VERSION ""

NS_ :

BS_:

BU_: HMI1 HMI2 VCU BMS MCU

BO_ 3221225472 VECTOR__INDEPENDENT_SIG_MSG: 0 Vector__XXX
 SG_ DBG_VCU__State : 16|8@1- (1,0) [0|0] "" Vector__XXX

BO_ 1952 VCU_Heartbeat: 2 VCU
 SG_ VCU__Version : 0|16@1+ (1,0) [0|0] "" Vector__XXX

BO_ 1953 HMI1_Heartbeat: 2 HMI1
 SG_ HMI1__Version : 0|16@1+ (1,0) [0|0] ""  VCU

BO_ 1954 HMI2_Heartbeat: 2 HMI2
 SG_ HMI2__Version : 0|16@1+ (1,0) [0|0] ""  VCU

BO_ 26 DFU_Progress: 8 VCU
 SG_ DFU__DeviceType : 0|32@1+ (1,0) [0|0] ""  HMI1
 SG_ DFU__Progress : 32|32@1- (1,0) [0|0] "%"  HMI1

BO_ 27 DFU_CRC: 4 HMI1
 SG_ DFU__CurrentCRC : 0|32@1+ (1,0) [0|0] ""  VCU

BO_ 28 DFU_Pra: 4 VCU
 SG_ DFU__FirmwareSize : 0|32@1+ (1,0) [0|0] ""  HMI1

BO_ 29 DFU_Init: 6 VCU
 SG_ DFU__FirmwareOffset : 0|32@1+ (1,0) [0|0] ""  HMI1
 SG_ DFU__BlockOffset : 32|16@1+ (1,0) [0|0] ""  HMI1

BO_ 30 DFU_Run: 8 VCU
 SG_ DFU__SubBlockOffset : 0|16@1+ (1,0) [0|0] ""  HMI1
 SG_ DFU__FirmwareData : 32|32@1+ (1,0) [0|0] ""  HMI1

BO_ 31 DFU_Pasca: 4 VCU
 SG_ DFU__NewestCRC : 0|32@1+ (1,0) [0|0] ""  HMI1

BO_ 42 VCU_SwitchControl: 8 VCU
 SG_ VCU__ABS_State : 0|1@1+ (1,0) [0|0] ""  HMI1
 SG_ VCU__MirroringState : 1|1@1+ (1,0) [0|0] ""  HMI1
 SG_ VCU__LampState : 2|1@1+ (1,0) [0|0] ""  HMI1
 SG_ VCU__ErrorState : 3|1@1+ (1,0) [0|0] ""  HMI1
 SG_ VCU__OverheatState : 4|1@1+ (1,0) [0|0] ""  HMI1
 SG_ VCU__FingerState : 5|1@1+ (1,0) [0|0] ""  HMI1
 SG_ VCU__RemoteState : 6|1@1+ (1,0) [0|0] ""  HMI1
 SG_ VCU__DaylightState : 7|1@1+ (1,0) [0|0] ""  HMI1
 SG_ VCU__SeinLeftState : 8|1@1+ (1,0) [0|0] ""  HMI1
 SG_ VCU__SeinRightState : 9|1@1+ (1,0) [0|0] ""  HMI1
 SG_ VCU__HbarReverseState : 10|1@1+ (1,0) [0|0] ""  HMI1
 SG_ VCU__BMSRun : 11|1@1+ (1,0) [0|0] ""  HMI1
 SG_ VCU__MCURun : 12|1@1+ (1,0) [0|0] ""  HMI1
 SG_ VCU__FingerBlink : 13|1@1+ (1,0) [0|0] ""  HMI1
 SG_ VCU__FingerError : 14|1@1+ (1,0) [0|0] ""  HMI1
 SG_ VCU__DriveMode : 16|2@1+ (1,0) [0|0] ""  HMI1
 SG_ VCU__TripMode : 18|2@1+ (1,0) [0|0] ""  HMI1
 SG_ VCU__ReportMode : 20|1@1+ (1,0) [0|0] ""  HMI1
 SG_ VCU__ModeState : 21|2@1+ (1,0) [0|0] ""  HMI1
 SG_ VCU__ModeSession : 23|1@1+ (1,0) [0|0] ""  HMI1
 SG_ VCU__Speed : 24|8@1+ (1,0) [0|0] "kph"  HMI1
 SG_ VCU__MCUDisCur : 32|8@1+ (1,0) [0|0] "A"  HMI1
 SG_ VCU__BMSSoc : 40|8@1+ (1,0) [0|0] "%"  HMI1
 SG_ VCU__NetSignal : 48|8@1+ (1,0) [0|0] "%"  HMI1
 SG_ VCU__VehicleState : 56|8@1- (1,0) [0|0] ""  HMI1

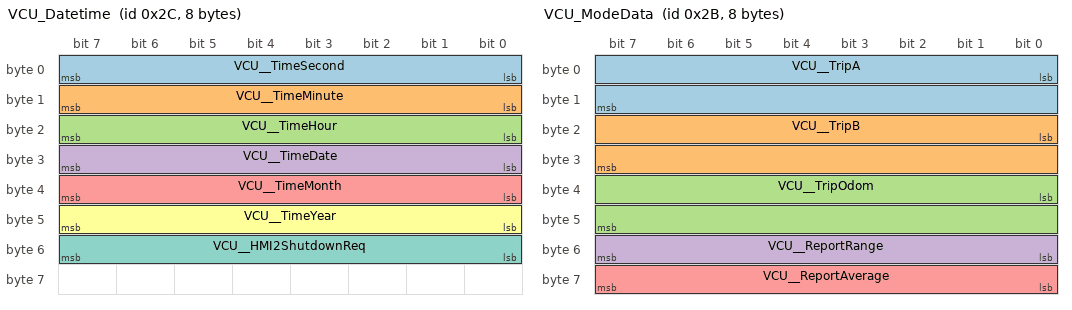
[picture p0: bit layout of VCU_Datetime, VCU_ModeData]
BO_ 44 VCU_Datetime: 8 VCU
 SG_ VCU__TimeSecond : 0|8@1+ (1,0) [0|0] ""  HMI2
 SG_ VCU__TimeMinute : 8|8@1+ (1,0) [0|0] ""  HMI2
 SG_ VCU__TimeHour : 16|8@1+ (1,0) [0|0] ""  HMI2
 SG_ VCU__TimeDate : 24|8@1+ (1,0) [0|0] ""  HMI2
 SG_ VCU__TimeMonth : 32|8@1+ (1,0) [0|0] ""  HMI2
 SG_ VCU__TimeYear : 40|8@1+ (1,0) [0|0] ""  HMI2
 SG_ VCU__HMI2ShutdownReq : 48|8@1+ (1,0) [0|0] ""  HMI2

BO_ 43 VCU_ModeData: 8 VCU
 SG_ VCU__TripA : 0|16@1+ (1,0) [0|0] "km"  HMI1
 SG_ VCU__TripB : 16|16@1+ (1,0) [0|0] "km"  HMI1
 SG_ VCU__TripOdom : 32|16@1+ (1,0) [0|0] "km"  HMI1
 SG_ VCU__ReportRange : 48|8@1+ (1,0) [0|0] "km"  HMI1
 SG_ VCU__ReportAverage : 56|8@1+ (1,0) [0|0] "km/kwh"  HMI1

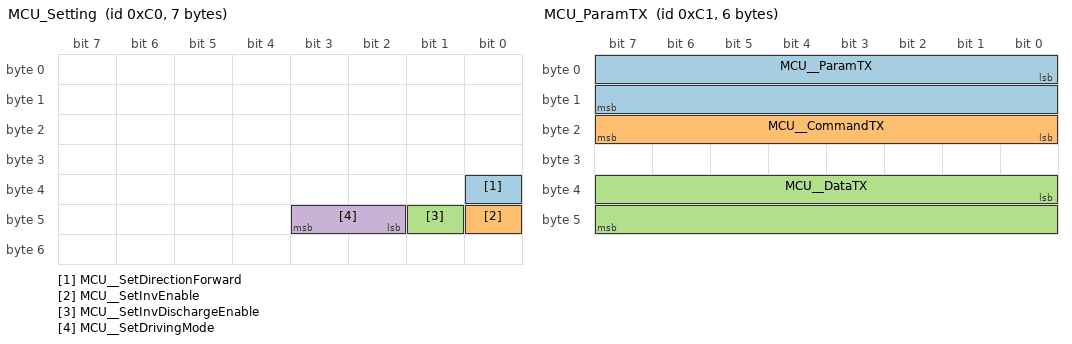
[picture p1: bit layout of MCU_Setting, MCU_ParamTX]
BO_ 192 MCU_Setting: 7 VCU
 SG_ MCU__SetDirectionForward : 32|1@1+ (1,0) [0|0] ""  MCU
 SG_ MCU__SetInvEnable : 40|1@1+ (1,0) [0|0] ""  MCU
 SG_ MCU__SetInvDischargeEnable : 41|1@1+ (1,0) [0|0] ""  MCU
 SG_ MCU__SetDrivingMode : 42|2@1+ (1,0) [0|0] ""  MCU

BO_ 193 MCU_ParamTX: 6 VCU
 SG_ MCU__ParamTX : 0|16@1+ (1,0) [0|0] ""  MCU
 SG_ MCU__CommandTX : 16|8@1+ (1,0) [0|0] ""  MCU
 SG_ MCU__DataTX : 32|16@1+ (1,0) [0|0] ""  MCU

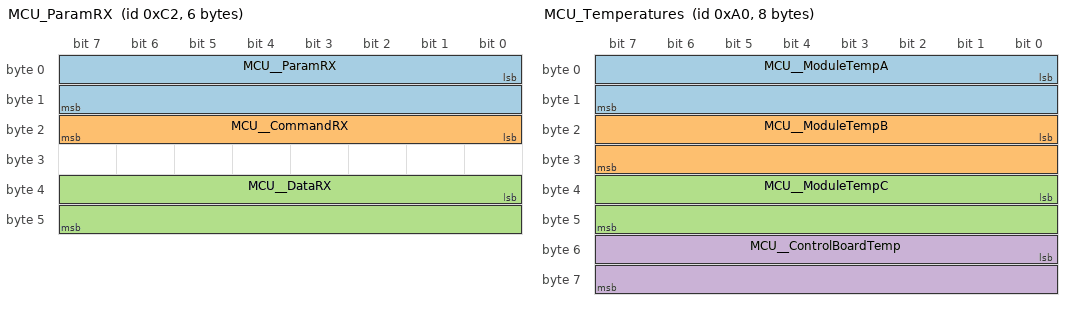
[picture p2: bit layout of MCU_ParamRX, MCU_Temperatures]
BO_ 194 MCU_ParamRX: 6 MCU
 SG_ MCU__ParamRX : 0|16@1+ (1,0) [0|0] ""  VCU
 SG_ MCU__CommandRX : 16|8@1+ (1,0) [0|0] ""  VCU
 SG_ MCU__DataRX : 32|16@1+ (1,0) [0|0] ""  VCU

BO_ 160 MCU_Temperatures: 8 MCU
 SG_ MCU__ModuleTempA : 0|16@1- (0.1,0) [0|0] "C"  VCU
 SG_ MCU__ModuleTempB : 16|16@1- (0.1,0) [0|0] "C"  VCU
 SG_ MCU__ModuleTempC : 32|16@1- (0.1,0) [0|0] "C"  VCU
 SG_ MCU__ControlBoardTemp : 48|16@1- (0.1,0) [0|0] "C"  VCU

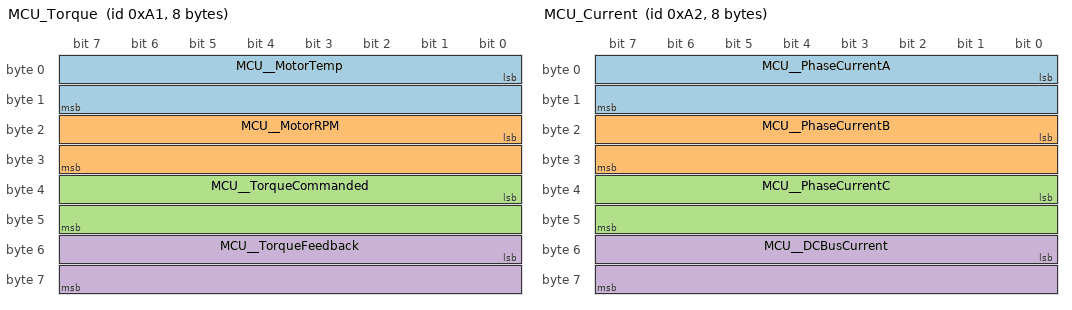
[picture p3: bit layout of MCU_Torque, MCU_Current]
BO_ 161 MCU_Torque: 8 MCU
 SG_ MCU__MotorTemp : 0|16@1- (0.1,0) [0|0] "C"  VCU
 SG_ MCU__MotorRPM : 16|16@1- (1,0) [0|0] "rpm"  VCU
 SG_ MCU__TorqueCommanded : 32|16@1- (0.1,0) [0|0] "Nm"  VCU
 SG_ MCU__TorqueFeedback : 48|16@1- (0.1,0) [0|0] "Nm"  VCU

BO_ 162 MCU_Current: 8 MCU
 SG_ MCU__PhaseCurrentA : 0|16@1- (0.1,0) [0|0] "A"  VCU
 SG_ MCU__PhaseCurrentB : 16|16@1- (0.1,0) [0|0] "A"  VCU
 SG_ MCU__PhaseCurrentC : 32|16@1- (0.1,0) [0|0] "A"  VCU
 SG_ MCU__DCBusCurrent : 48|16@1- (0.1,0) [0|0] "A"  VCU

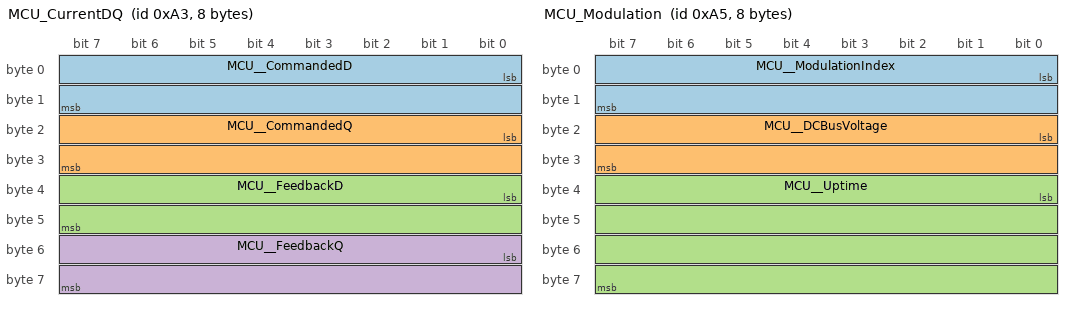
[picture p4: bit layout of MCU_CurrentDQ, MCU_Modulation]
BO_ 163 MCU_CurrentDQ: 8 MCU
 SG_ MCU__CommandedD : 0|16@1- (0.1,0) [0|0] "A"  VCU
 SG_ MCU__CommandedQ : 16|16@1- (0.1,0) [0|0] "A"  VCU
 SG_ MCU__FeedbackD : 32|16@1- (0.1,0) [0|0] "A"  VCU
 SG_ MCU__FeedbackQ : 48|16@1- (0.1,0) [0|0] "A"  VCU

BO_ 164 MCU_FaultCodes: 8 MCU
 SG_ MCU__FaultPOST : 0|32@1+ (1,0) [0|0] ""  VCU
 SG_ MCU__FaultRUN : 32|32@1+ (1,0) [0|0] ""  VCU

BO_ 165 MCU_Modulation: 8 MCU
 SG_ MCU__ModulationIndex : 0|16@1- (0.001,0) [0|0] ""  VCU
 SG_ MCU__DCBusVoltage : 16|16@1- (0.1,0) [0|0] "V"  VCU
 SG_ MCU__Uptime : 32|32@1+ (0.003,0) [0|0] "s"  VCU

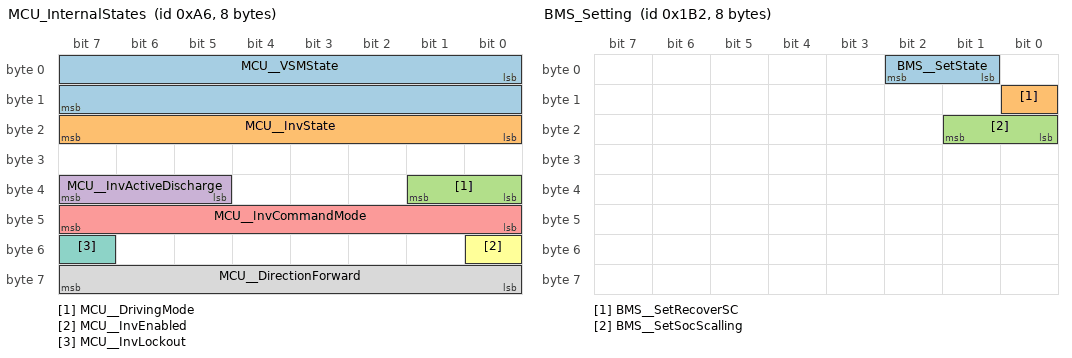
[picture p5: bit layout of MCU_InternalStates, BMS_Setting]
BO_ 166 MCU_InternalStates: 8 MCU
 SG_ MCU__VSMState : 0|16@1+ (1,0) [0|0] ""  VCU
 SG_ MCU__InvState : 16|8@1+ (1,0) [0|0] ""  VCU
 SG_ MCU__DrivingMode : 32|2@1+ (1,0) [0|0] ""  VCU
 SG_ MCU__InvActiveDischarge : 37|3@1+ (1,0) [0|0] ""  VCU
 SG_ MCU__InvCommandMode : 40|8@1+ (1,0) [0|0] ""  VCU
 SG_ MCU__InvEnabled : 48|1@1+ (1,0) [0|0] ""  VCU
 SG_ MCU__InvLockout : 55|1@1+ (1,0) [0|0] ""  VCU
 SG_ MCU__DirectionForward : 56|8@1+ (1,0) [0|0] ""  VCU

BO_ 434 BMS_Setting: 8 VCU
 SG_ BMS__SetState : 1|2@1+ (1,0) [0|0] ""  BMS
 SG_ BMS__SetRecoverSC : 8|1@1+ (1,0) [0|0] ""  BMS
 SG_ BMS__SetSocScalling : 16|2@1+ (1,0) [0|0] ""  BMS

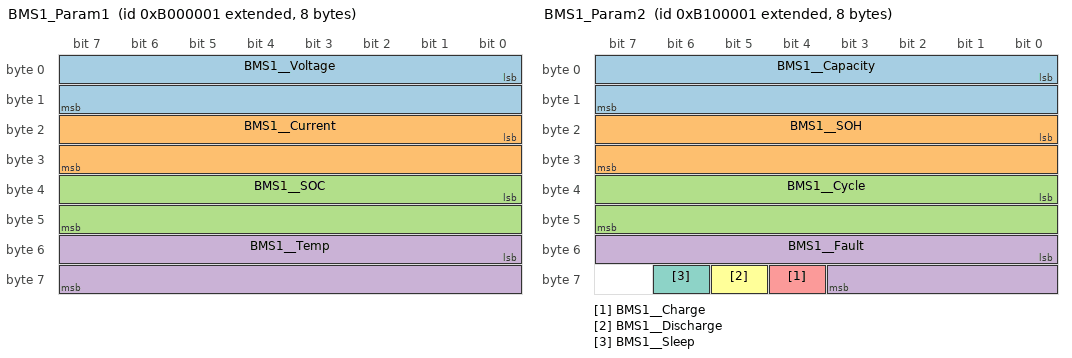
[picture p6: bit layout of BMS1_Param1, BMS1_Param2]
BO_ 2332033025 BMS1_Param1: 8 BMS
 SG_ BMS1__Voltage : 0|16@1+ (0.01,0) [0|0] "V"  VCU
 SG_ BMS1__Current : 16|16@1+ (0.1,0) [0|0] "A"  VCU
 SG_ BMS1__SOC : 32|16@1+ (1,0) [0|0] "%"  VCU
 SG_ BMS1__Temp : 48|16@1+ (1,-40) [0|0] "C"  VCU

BO_ 2333081601 BMS1_Param2: 8 BMS
 SG_ BMS1__Capacity : 0|16@1+ (0.1,0) [0|0] "Ah"  VCU
 SG_ BMS1__SOH : 16|16@1+ (1,0) [0|0] "%"  VCU
 SG_ BMS1__Cycle : 32|16@1+ (1,0) [0|0] ""  VCU
 SG_ BMS1__Fault : 48|12@1+ (1,0) [0|0] ""  VCU
 SG_ BMS1__Charge : 60|1@1+ (1,0) [0|0] ""  VCU
 SG_ BMS1__Discharge : 61|1@1+ (1,0) [0|0] ""  VCU
 SG_ BMS1__Sleep : 62|1@1+ (1,0) [0|0] ""  VCU

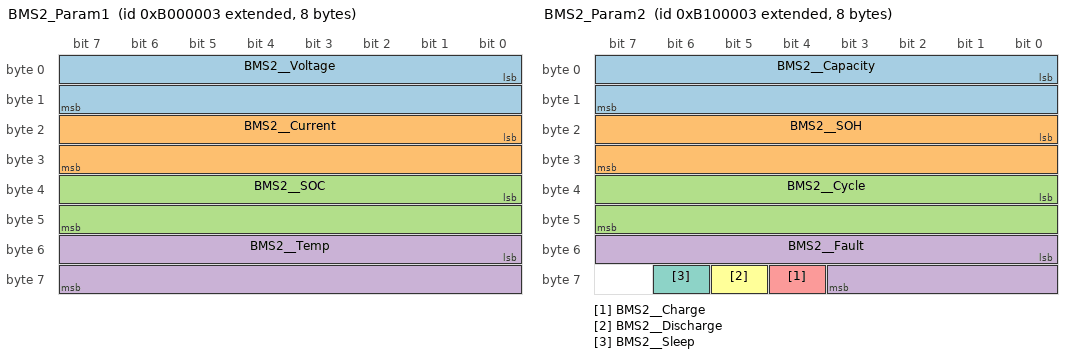
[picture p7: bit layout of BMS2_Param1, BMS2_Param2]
BO_ 2332033027 BMS2_Param1: 8 BMS
 SG_ BMS2__Voltage : 0|16@1+ (0.01,0) [0|0] "V"  VCU
 SG_ BMS2__Current : 16|16@1+ (0.1,0) [0|0] "A"  VCU
 SG_ BMS2__SOC : 32|16@1+ (1,0) [0|0] "%"  VCU
 SG_ BMS2__Temp : 48|16@1+ (1,-40) [0|0] "C"  VCU

BO_ 2333081603 BMS2_Param2: 8 BMS
 SG_ BMS2__Capacity : 0|16@1+ (0.1,0) [0|0] "Ah"  VCU
 SG_ BMS2__SOH : 16|16@1+ (1,0) [0|0] "%"  VCU
 SG_ BMS2__Cycle : 32|16@1+ (1,0) [0|0] ""  VCU
 SG_ BMS2__Fault : 48|12@1+ (1,0) [0|0] ""  VCU
 SG_ BMS2__Charge : 60|1@1+ (1,0) [0|0] ""  VCU
 SG_ BMS2__Discharge : 61|1@1+ (1,0) [0|0] ""  VCU
 SG_ BMS2__Sleep : 62|1@1+ (1,0) [0|0] ""  VCU

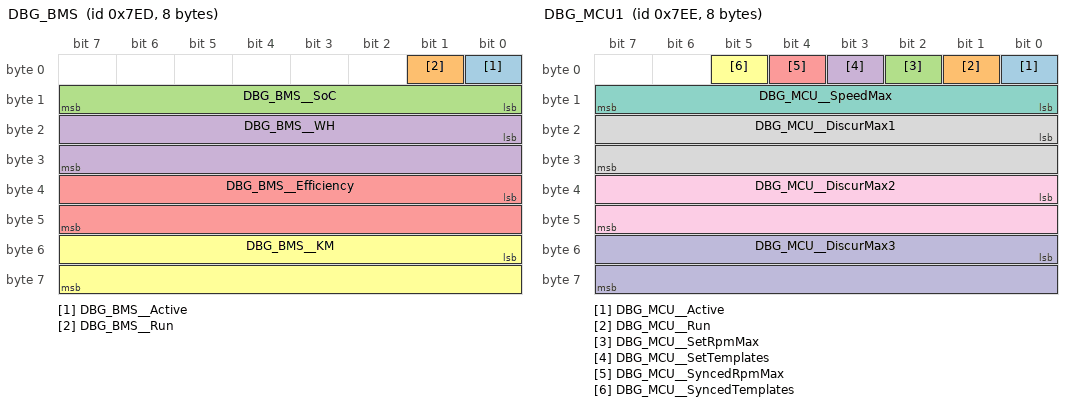
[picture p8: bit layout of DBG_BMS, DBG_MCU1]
BO_ 2029 DBG_BMS: 8 VCU
 SG_ DBG_BMS__Active : 0|1@1+ (1,0) [0|0] "" Vector__XXX
 SG_ DBG_BMS__Run : 1|1@1+ (1,0) [0|0] "" Vector__XXX
 SG_ DBG_BMS__SoC : 8|8@1+ (1,0) [0|0] "%" Vector__XXX
 SG_ DBG_BMS__WH : 16|16@1+ (0.1,0) [0|0] "wh" Vector__XXX
 SG_ DBG_BMS__Efficiency : 32|16@1+ (0.1,0) [0|0] "km/kwh" Vector__XXX
 SG_ DBG_BMS__KM : 48|16@1+ (0.1,0) [0|0] "km" Vector__XXX

BO_ 2030 DBG_MCU1: 8 VCU
 SG_ DBG_MCU__Active : 0|1@1+ (1,0) [0|0] "" Vector__XXX
 SG_ DBG_MCU__Run : 1|1@1+ (1,0) [0|0] "" Vector__XXX
 SG_ DBG_MCU__SetRpmMax : 2|1@1+ (1,0) [0|0] "rpm" Vector__XXX
 SG_ DBG_MCU__SetTemplates : 3|1@1+ (1,0) [0|0] "" Vector__XXX
 SG_ DBG_MCU__SyncedRpmMax : 4|1@1+ (1,0) [0|0] "" Vector__XXX
 SG_ DBG_MCU__SyncedTemplates : 5|1@1+ (1,0) [0|0] "" Vector__XXX
 SG_ DBG_MCU__SpeedMax : 8|8@1+ (1,0) [0|0] "kph" Vector__XXX
 SG_ DBG_MCU__DiscurMax1 : 16|16@1- (1,0) [0|0] "A" Vector__XXX
 SG_ DBG_MCU__DiscurMax2 : 32|16@1- (1,0) [0|0] "A" Vector__XXX
 SG_ DBG_MCU__DiscurMax3 : 48|16@1- (1,0) [0|0] "A" Vector__XXX

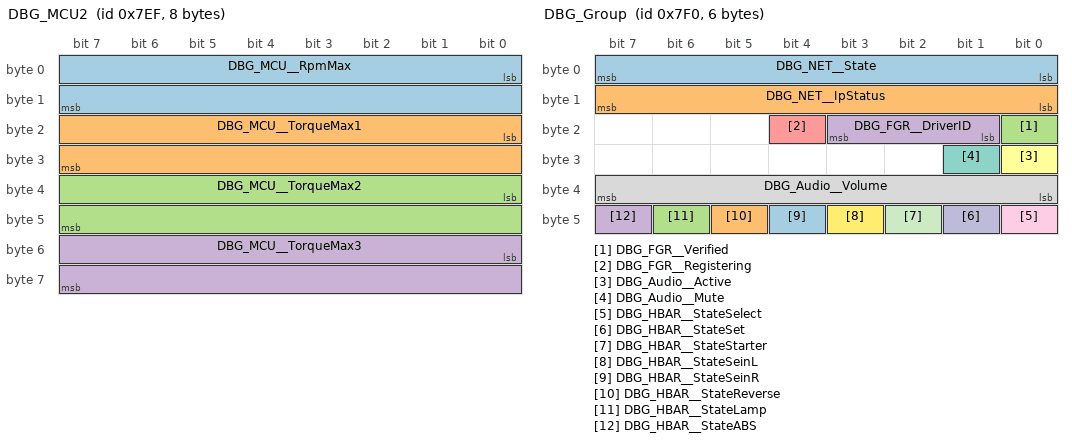
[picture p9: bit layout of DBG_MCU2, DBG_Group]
BO_ 2031 DBG_MCU2: 8 VCU
 SG_ DBG_MCU__RpmMax : 0|16@1- (1,0) [0|0] "rpm" Vector__XXX
 SG_ DBG_MCU__TorqueMax1 : 16|16@1- (0.1,0) [0|0] "Nm" Vector__XXX
 SG_ DBG_MCU__TorqueMax2 : 32|16@1- (0.1,0) [0|0] "Nm" Vector__XXX
 SG_ DBG_MCU__TorqueMax3 : 48|16@1- (0.1,0) [0|0] "Nm" Vector__XXX

BO_ 2032 DBG_Group: 6 VCU
 SG_ DBG_NET__State : 0|8@1- (1,0) [0|0] "" Vector__XXX
 SG_ DBG_NET__IpStatus : 8|8@1- (1,0) [0|0] "" Vector__XXX
 SG_ DBG_FGR__Verified : 16|1@1+ (1,0) [0|0] "" Vector__XXX
 SG_ DBG_FGR__DriverID : 17|3@1+ (1,0) [0|0] "" Vector__XXX
 SG_ DBG_FGR__Registering : 20|1@1+ (1,0) [0|0] "" Vector__XXX
 SG_ DBG_Audio__Active : 24|1@1+ (1,0) [0|0] "" Vector__XXX
 SG_ DBG_Audio__Mute : 25|1@1+ (1,0) [0|0] "" Vector__XXX
 SG_ DBG_Audio__Volume : 32|8@1+ (1,0) [0|0] "%" Vector__XXX
 SG_ DBG_HBAR__StateSelect : 40|1@1+ (1,0) [0|0] "" Vector__XXX
 SG_ DBG_HBAR__StateSet : 41|1@1+ (1,0) [0|0] "" Vector__XXX
 SG_ DBG_HBAR__StateStarter : 42|1@1+ (1,0) [0|0] "" Vector__XXX
 SG_ DBG_HBAR__StateSeinL : 43|1@1+ (1,0) [0|0] "" Vector__XXX
 SG_ DBG_HBAR__StateSeinR : 44|1@1+ (1,0) [0|0] "" Vector__XXX
 SG_ DBG_HBAR__StateReverse : 45|1@1+ (1,0) [0|0] "" Vector__XXX
 SG_ DBG_HBAR__StateLamp : 46|1@1+ (1,0) [0|0] "" Vector__XXX
 SG_ DBG_HBAR__StateABS : 47|1@1+ (1,0) [0|0] "" Vector__XXX

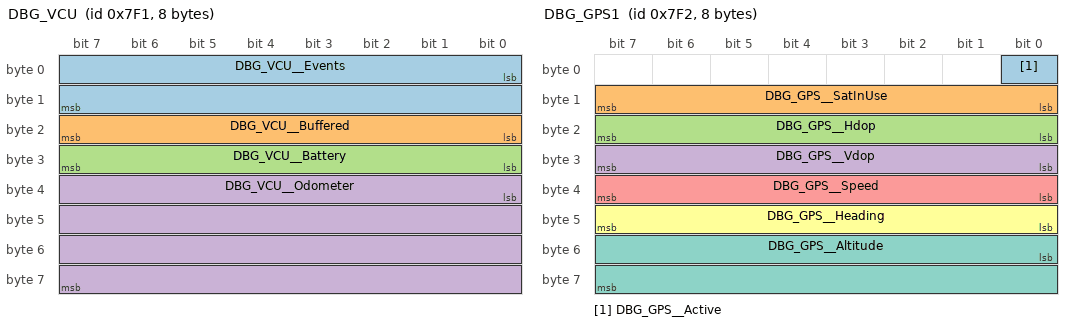
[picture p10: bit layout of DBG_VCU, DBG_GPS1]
BO_ 2033 DBG_VCU: 8 VCU
 SG_ DBG_VCU__Events : 0|16@1+ (1,0) [0|0] "" Vector__XXX
 SG_ DBG_VCU__Buffered : 16|8@1+ (1,0) [0|0] "" Vector__XXX
 SG_ DBG_VCU__Battery : 24|8@1+ (18,0) [0|0] "mV" Vector__XXX
 SG_ DBG_VCU__Odometer : 32|32@1+ (1,0) [0|0] "m" Vector__XXX

BO_ 2034 DBG_GPS1: 8 VCU
 SG_ DBG_GPS__Active : 0|1@1+ (1,0) [0|0] "" Vector__XXX
 SG_ DBG_GPS__SatInUse : 8|8@1+ (1,0) [0|0] "" Vector__XXX
 SG_ DBG_GPS__Hdop : 16|8@1+ (0.1,0) [0|0] "" Vector__XXX
 SG_ DBG_GPS__Vdop : 24|8@1+ (0.1,0) [0|0] "" Vector__XXX
 SG_ DBG_GPS__Speed : 32|8@1+ (1,0) [0|0] "kph" Vector__XXX
 SG_ DBG_GPS__Heading : 40|8@1+ (2,0) [0|0] "deg" Vector__XXX
 SG_ DBG_GPS__Altitude : 48|16@1+ (0.1,0) [0|0] "m" Vector__XXX

BO_ 2035 DBG_GPS2: 8 VCU
 SG_ DBG_GPS__Longitude : 0|32@1- (1e-07,0) [0|0] "" Vector__XXX
 SG_ DBG_GPS__Latitude : 32|32@1- (1e-07,0) [0|0] "" Vector__XXX

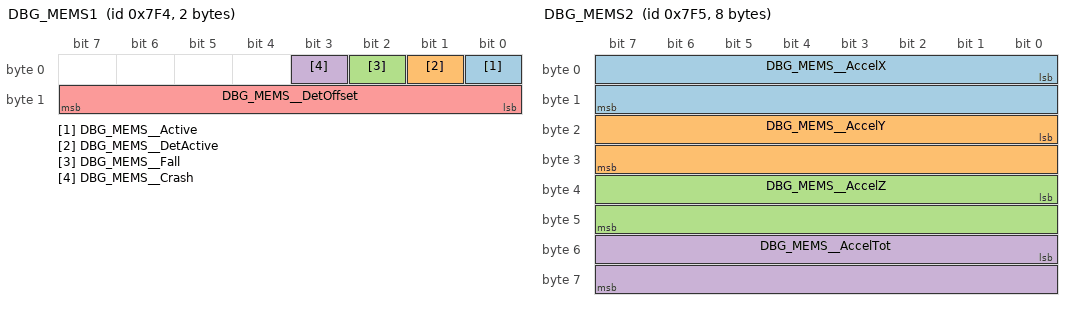
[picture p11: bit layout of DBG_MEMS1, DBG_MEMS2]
BO_ 2036 DBG_MEMS1: 2 VCU
 SG_ DBG_MEMS__Active : 0|1@1+ (1,0) [0|0] "" Vector__XXX
 SG_ DBG_MEMS__DetActive : 1|1@1+ (1,0) [0|0] "" Vector__XXX
 SG_ DBG_MEMS__Fall : 2|1@1+ (1,0) [0|0] "" Vector__XXX
 SG_ DBG_MEMS__Crash : 3|1@1+ (1,0) [0|0] "" Vector__XXX
 SG_ DBG_MEMS__DetOffset : 8|8@1+ (1,0) [0|0] "deg" Vector__XXX

BO_ 2037 DBG_MEMS2: 8 VCU
 SG_ DBG_MEMS__AccelX : 0|16@1- (0.01,0) [0|0] "g" Vector__XXX
 SG_ DBG_MEMS__AccelY : 16|16@1- (0.01,0) [0|0] "g" Vector__XXX
 SG_ DBG_MEMS__AccelZ : 32|16@1- (0.01,0) [0|0] "g" Vector__XXX
 SG_ DBG_MEMS__AccelTot : 48|16@1+ (0.01,0) [0|0] "g" Vector__XXX

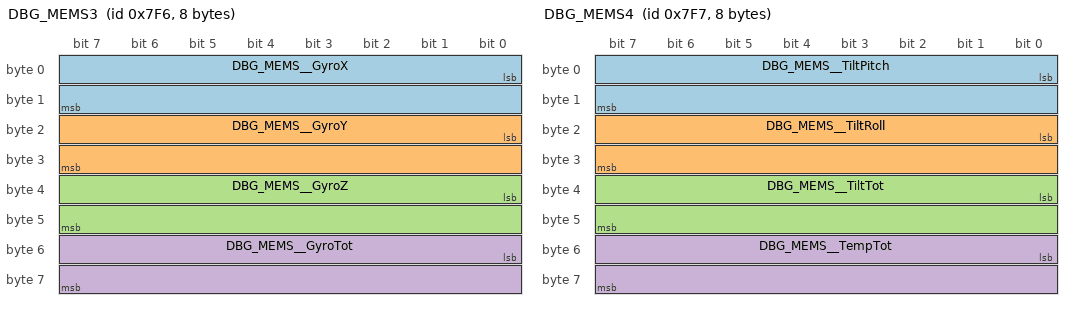
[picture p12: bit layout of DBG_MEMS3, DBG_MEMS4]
BO_ 2038 DBG_MEMS3: 8 VCU
 SG_ DBG_MEMS__GyroX : 0|16@1- (0.1,0) [0|0] "rad/s" Vector__XXX
 SG_ DBG_MEMS__GyroY : 16|16@1- (0.1,0) [0|0] "rad/s" Vector__XXX
 SG_ DBG_MEMS__GyroZ : 32|16@1- (0.1,0) [0|0] "rad/s" Vector__XXX
 SG_ DBG_MEMS__GyroTot : 48|16@1+ (0.1,0) [0|0] "rad/s" Vector__XXX

BO_ 2039 DBG_MEMS4: 8 VCU
 SG_ DBG_MEMS__TiltPitch : 0|16@1- (0.1,0) [0|0] "deg" Vector__XXX
 SG_ DBG_MEMS__TiltRoll : 16|16@1- (0.1,0) [0|0] "deg" Vector__XXX
 SG_ DBG_MEMS__TiltTot : 32|16@1+ (0.1,0) [0|0] "deg" Vector__XXX
 SG_ DBG_MEMS__TempTot : 48|16@1+ (0.1,0) [0|0] "C" Vector__XXX

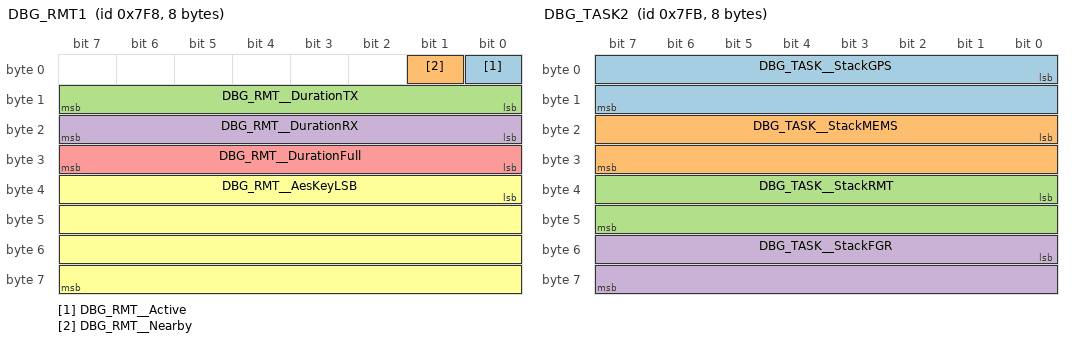
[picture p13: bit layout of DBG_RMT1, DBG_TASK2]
BO_ 2040 DBG_RMT1: 8 VCU
 SG_ DBG_RMT__Active : 0|1@1+ (1,0) [0|0] "" Vector__XXX
 SG_ DBG_RMT__Nearby : 1|1@1+ (1,0) [0|0] "" Vector__XXX
 SG_ DBG_RMT__DurationTX : 8|8@1+ (1,0) [0|0] "ms" Vector__XXX
 SG_ DBG_RMT__DurationRX : 16|8@1+ (1,0) [0|0] "ms" Vector__XXX
 SG_ DBG_RMT__DurationFull : 24|8@1+ (1,0) [0|0] "ms" Vector__XXX
 SG_ DBG_RMT__AesKeyLSB : 32|32@1+ (1,0) [0|0] "" Vector__XXX

BO_ 2041 DBG_RMT2: 8 VCU
 SG_ DBG_RMT__TickPing : 0|32@1+ (1,0) [0|0] "" Vector__XXX
 SG_ DBG_RMT__TickHeartbeat : 32|32@1+ (1,0) [0|0] "" Vector__XXX

BO_ 2042 DBG_TASK1: 8 VCU
 SG_ DBG_TASK__StackManager : 0|16@1+ (1,0) [0|0] "B" Vector__XXX
 SG_ DBG_TASK__StackNetwork : 16|16@1+ (1,0) [0|0] "B" Vector__XXX
 SG_ DBG_TASK__StackReporter : 32|16@1+ (1,0) [0|0] "B" Vector__XXX
 SG_ DBG_TASK__StackCommand : 40|16@1+ (1,0) [0|0] "B" Vector__XXX

BO_ 2043 DBG_TASK2: 8 VCU
 SG_ DBG_TASK__StackGPS : 0|16@1+ (1,0) [0|0] "B" Vector__XXX
 SG_ DBG_TASK__StackMEMS : 16|16@1+ (1,0) [0|0] "B" Vector__XXX
 SG_ DBG_TASK__StackRMT : 32|16@1+ (1,0) [0|0] "B" Vector__XXX
 SG_ DBG_TASK__StackFGR : 48|16@1+ (1,0) [0|0] "B" Vector__XXX

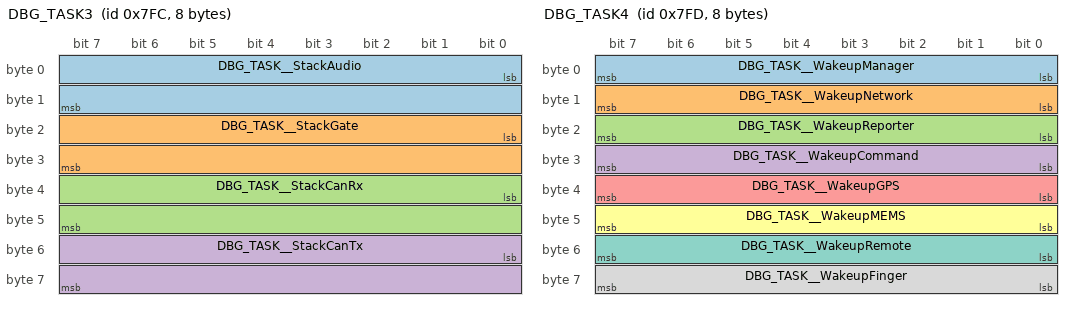
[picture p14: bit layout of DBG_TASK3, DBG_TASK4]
BO_ 2044 DBG_TASK3: 8 VCU
 SG_ DBG_TASK__StackAudio : 0|16@1+ (1,0) [0|0] "B" Vector__XXX
 SG_ DBG_TASK__StackGate : 16|16@1+ (1,0) [0|0] "B" Vector__XXX
 SG_ DBG_TASK__StackCanRx : 32|16@1+ (1,0) [0|0] "B" Vector__XXX
 SG_ DBG_TASK__StackCanTx : 48|16@1+ (1,0) [0|0] "B" Vector__XXX

BO_ 2045 DBG_TASK4: 8 VCU
 SG_ DBG_TASK__WakeupManager : 0|8@1+ (1,0) [0|0] "s" Vector__XXX
 SG_ DBG_TASK__WakeupNetwork : 8|8@1+ (1,0) [0|0] "s" Vector__XXX
 SG_ DBG_TASK__WakeupReporter : 16|8@1+ (1,0) [0|0] "s" Vector__XXX
 SG_ DBG_TASK__WakeupCommand : 24|8@1+ (1,0) [0|0] "s" Vector__XXX
 SG_ DBG_TASK__WakeupGPS : 32|8@1+ (1,0) [0|0] "s" Vector__XXX
 SG_ DBG_TASK__WakeupMEMS : 40|8@1+ (1,0) [0|0] "s" Vector__XXX
 SG_ DBG_TASK__WakeupRemote : 48|8@1+ (1,0) [0|0] "s" Vector__XXX
 SG_ DBG_TASK__WakeupFinger : 56|8@1+ (1,0) [0|0] "s" Vector__XXX

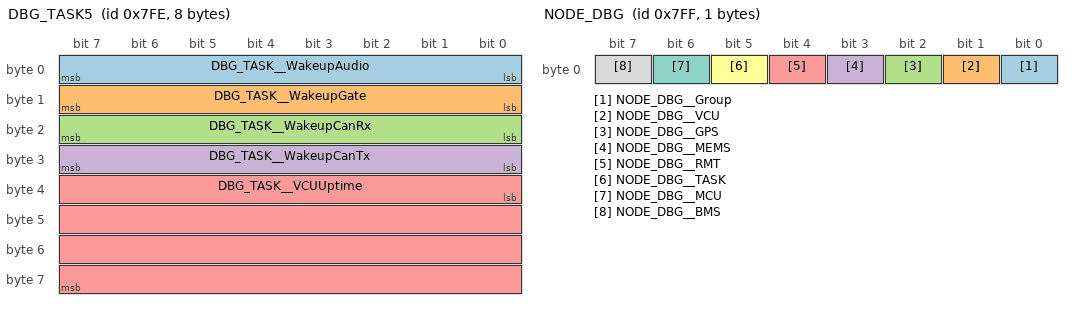
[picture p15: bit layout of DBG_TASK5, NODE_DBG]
BO_ 2046 DBG_TASK5: 8 VCU
 SG_ DBG_TASK__WakeupAudio : 0|8@1+ (1,0) [0|0] "s" Vector__XXX
 SG_ DBG_TASK__WakeupGate : 8|8@1+ (1,0) [0|0] "s" Vector__XXX
 SG_ DBG_TASK__WakeupCanRx : 16|8@1+ (1,0) [0|0] "s" Vector__XXX
 SG_ DBG_TASK__WakeupCanTx : 24|8@1+ (1,0) [0|0] "s" Vector__XXX
 SG_ DBG_TASK__VCUUptime : 32|32@1+ (1,0) [0|0] "s" Vector__XXX

BO_ 2047 NODE_DBG: 1 Vector__XXX
 SG_ NODE_DBG__Group : 0|1@1+ (1,0) [0|0] ""  VCU
 SG_ NODE_DBG__VCU : 1|1@1+ (1,0) [0|0] ""  VCU
 SG_ NODE_DBG__GPS : 2|1@1+ (1,0) [0|0] ""  VCU
 SG_ NODE_DBG__MEMS : 3|1@1+ (1,0) [0|0] ""  VCU
 SG_ NODE_DBG__RMT : 4|1@1+ (1,0) [0|0] ""  VCU
 SG_ NODE_DBG__TASK : 5|1@1+ (1,0) [0|0] ""  VCU
 SG_ NODE_DBG__MCU : 6|1@1+ (1,0) [0|0] ""  VCU
 SG_ NODE_DBG__BMS : 7|1@1+ (1,0) [0|0] "" Vector__XXX

BA_DEF_ BO_  "GenMsgBackgroundColor" STRING ;
BA_DEF_ BO_  "GenMsgForegroundColor" STRING ;
BA_DEF_DEF_  "GenMsgBackgroundColor" "#ffffff";
BA_DEF_DEF_  "GenMsgForegroundColor" "#000000";
VAL_ 42 VCU__DriveMode 0 "HBAR_M_DRIVE_ECONOMY" 1 "HBAR_M_DRIVE_STANDARD" 2 "HBAR_M_DRIVE_SPORT" ;
VAL_ 42 VCU__TripMode 0 "HBAR_M_TRIP_A" 1 "HBAR_M_TRIP_B" 2 "HBAR_M_TRIP_ODO" ;
VAL_ 42 VCU__ReportMode 0 "HBAR_M_REPORT_RANGE" 1 "HBAR_M_REPORT_AVERAGE" ;
VAL_ 42 VCU__ModeState 0 "HBAR_M_DRIVE" 1 "HBAR_M_TRIP" 2 "HBAR_M_REPORT" ;
VAL_ 42 VCU__VehicleState 0 "VEHICLE_NORMAL" 1 "VEHICLE_STANDBY" 2 "VEHICLE_READY" 3 "VEHICLE_RUN" ;
VAL_ 192 MCU__SetDrivingMode 0 "MCU_DRIVE_ECONOMIC" 1 "MCU_DRIVE_STANDARD" 2 "MCU_DRIVE_SPORT" ;
VAL_ 166 MCU__DrivingMode 0 "MCU_DRIVE_ECONOMIC" 1 "MCU_DRIVE_STANDARD" 2 "MCU_DRIVE_SPORT" ;
VAL_ 434 BMS__SetState 0 "BMS_IDLE" 1 "BMS_DISCHARGE" 2 "BMS_CHARGE" 3 "BMS_FULL" ;
VAL_ 434 BMS__SetSocScalling 0 "SCALE_15_85" 1 "SCALE_20_80" 2 "SCALE_10_90" 3 "SCALE_0_100" ;
VAL_ 2032 DBG_NET__State -1 "SIM_STATE_DOWN" 0 "SIM_STATE_READY" 1 "SIM_STATE_CONFIGURED" 2 "SIM_STATE_NETWORK_ON" 3 "SIM_STATE_GPRS_ON" 4 "SIM_STATE_PDP_ON" 5 "SIM_STATE_INTERNET_ON" 6 "SIM_STATE_SERVER_ON" 7 "SIM_STATE_MQTT_ON" ;
VAL_ 2032 DBG_NET__IpStatus -1 "CIPSTAT_UNKNOWN" 0 "CIPSTAT_IP_INITIAL" 1 "CIPSTAT_IP_START" 2 "CIPSTAT_IP_CONFIG" 3 "CIPSTAT_IP_GPRSACT" 4 "CIPSTAT_IP_STATUS" 5 "CIPSTAT_CONNECTING" 6 "CIPSTAT_CONNECT_OK" 7 "CIPSTAT_CLOSING" 8 "CIPSTAT_CLOSED" 9 "CIPSTAT_PDP_DEACT" ;
